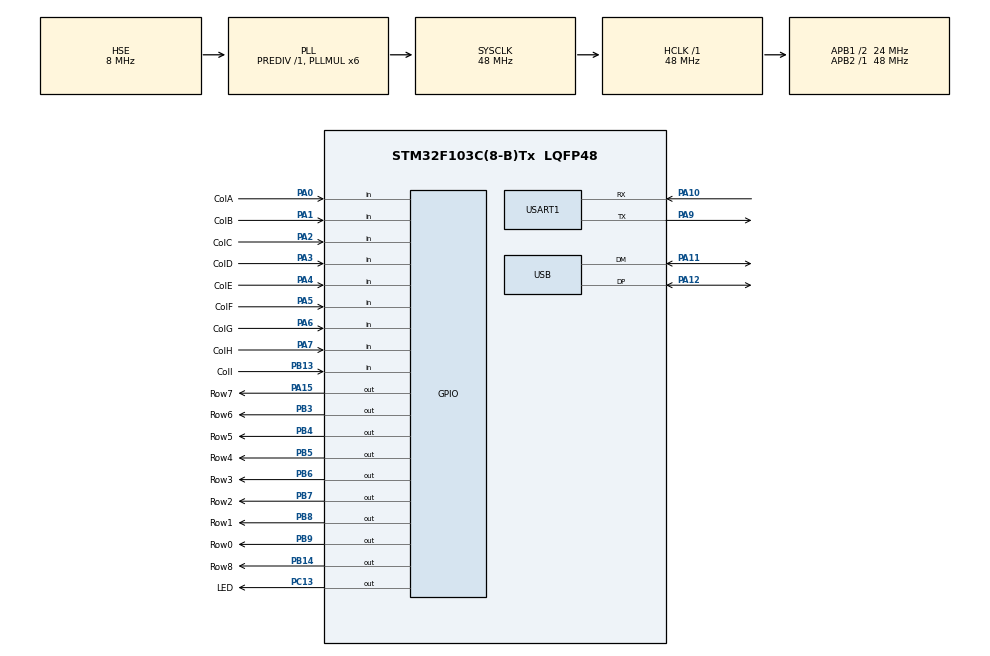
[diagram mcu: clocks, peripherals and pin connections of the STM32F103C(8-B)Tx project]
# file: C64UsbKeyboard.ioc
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FREERTOS.Tasks01=defaultTask,24,128,StartDefaultTask,Default,NULL,Dynamic,NULL,NULL;applicationTask,27,1024,StartApplicationTask,Default,NULL,Static,applicationTaskBuffer,applicationTaskControlBlock
FREERTOS.configUSE_NEWLIB_REENTRANT=1
Mcu.Family=STM32F1
Mcu.Name=STM32F103C(8-B)Tx
Mcu.Package=LQFP48
NVIC.PriorityGroup=NVIC_PRIORITYGROUP_4
NVIC.TIM4_IRQn=true\:15\:0\:false\:false\:true\:false\:false\:true\:true
NVIC.TimeBase=TIM4_IRQn
NVIC.TimeBaseIP=TIM4
NVIC.USART1_IRQn=true\:5\:0\:false\:false\:true\:true\:true\:true\:true
NVIC.USB_LP_CAN1_RX0_IRQn=true\:5\:0\:false\:false\:true\:true\:false\:true\:true
PA0-WKUP.GPIO_Label=ColA
PA0-WKUP.GPIO_PuPd=GPIO_PULLUP
PA0-WKUP.Signal=GPIO_Input
PA1.GPIO_Label=ColB
PA1.GPIO_PuPd=GPIO_PULLUP
PA1.Signal=GPIO_Input
PA10.Mode=Asynchronous
PA10.Signal=USART1_RX
PA11.Mode=Device
PA11.Signal=USB_DM
PA12.Mode=Device
PA12.Signal=USB_DP
PA13.Mode=Serial_Wire
PA13.Signal=SYS_JTMS-SWDIO
PA14.Mode=Serial_Wire
PA14.Signal=SYS_JTCK-SWCLK
PA15.GPIO_Label=Row7
PA15.Signal=GPIO_Output
PA2.GPIO_Label=ColC
PA2.GPIO_PuPd=GPIO_PULLUP
PA2.Signal=GPIO_Input
PA3.GPIO_Label=ColD
PA3.GPIO_PuPd=GPIO_PULLUP
PA3.Signal=GPIO_Input
PA4.GPIO_Label=ColE
PA4.GPIO_PuPd=GPIO_PULLUP
PA4.Signal=GPIO_Input
PA5.GPIO_Label=ColF
PA5.GPIO_PuPd=GPIO_PULLUP
PA5.Signal=GPIO_Input
PA6.GPIO_Label=ColG
PA6.GPIO_PuPd=GPIO_PULLUP
PA6.Signal=GPIO_Input
PA7.GPIO_Label=ColH
PA7.GPIO_PuPd=GPIO_PULLUP
PA7.Signal=GPIO_Input
PA9.Mode=Asynchronous
PA9.Signal=USART1_TX
PB13.GPIO_Label=ColI
PB13.GPIO_PuPd=GPIO_PULLUP
PB13.Signal=GPIO_Input
PB14.GPIO_Label=Row8
PB14.Signal=GPIO_Output
PB3.GPIO_Label=Row6
PB3.Signal=GPIO_Output
PB4.GPIO_Label=Row5
PB4.Signal=GPIO_Output
PB5.GPIO_Label=Row4
PB5.Signal=GPIO_Output
PB6.GPIO_Label=Row3
PB6.Signal=GPIO_Output
PB7.GPIO_Label=Row2
PB7.Signal=GPIO_Output
PB8.GPIO_Label=Row1
PB8.Signal=GPIO_Output
PB9.GPIO_Label=Row0
PB9.Signal=GPIO_Output
PC13-TAMPER-RTC.GPIO_Label=LED
PC13-TAMPER-RTC.Signal=GPIO_Output
PC14-OSC32_IN.Mode=LSE-External-Oscillator
PC14-OSC32_IN.Signal=RCC_OSC32_IN
PC15-OSC32_OUT.Mode=LSE-External-Oscillator
PC15-OSC32_OUT.Signal=RCC_OSC32_OUT
PD0-OSC_IN.Mode=HSE-External-Oscillator
PD0-OSC_IN.Signal=RCC_OSC_IN
PD1-OSC_OUT.Mode=HSE-External-Oscillator
PD1-OSC_OUT.Signal=RCC_OSC_OUT
ProjectManager.HeapSize=0x200
ProjectManager.StackSize=0x400
ProjectManager.TargetToolchain=STM32CubeIDE
RCC.AHBFreq_Value=48000000
RCC.APB1CLKDivider=RCC_HCLK_DIV2
RCC.APB1Freq_Value=24000000
RCC.APB1TimFreq_Value=48000000
RCC.APB2Freq_Value=48000000
RCC.APB2TimFreq_Value=48000000
RCC.HCLKFreq_Value=48000000
RCC.PLLMUL=RCC_PLL_MUL6
RCC.SYSCLKFreq_VALUE=48000000
RCC.SYSCLKSource=RCC_SYSCLKSOURCE_PLLCLK
RCC.USBFreq_Value=48000000
USART1.VirtualMode=VM_ASYNC
USB_DEVICE.CLASS_NAME_FS=HID
USB_DEVICE.PRODUCT_STRING_HID_FS=C64Keyboard
USB_DEVICE.VirtualMode=Hid
USB_DEVICE.VirtualModeFS=Hid_FS
VP_FREERTOS_VS_CMSIS_V2.Mode=CMSIS_V2
VP_SYS_VS_tim4.Mode=TIM4
VP_USB_DEVICE_VS_USB_DEVICE_HID_FS.Mode=HID_FS
board=custom

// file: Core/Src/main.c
/* USER CODE BEGIN Header */
/**
  ******************************************************************************
  * @file           : main.c
  * @brief          : Main program body
  ******************************************************************************
  * @attention
  *
  * Copyright (c) 2026 STMicroelectronics.
  * All rights reserved.
  *
  * This software is licensed under terms that can be found in the LICENSE file
  * in the root directory of this software component.
  * If no LICENSE file comes with this software, it is provided AS-IS.
  *
  ******************************************************************************
  */

// https://www.instructables.com/STM32-As-HID-USB-Keyboard-STM32-Tutorials/

/* USER CODE END Header */
#include "main.h"
#include "cmsis_os.h"
#include "usb_device.h"

/* USER CODE BEGIN Includes */
#include "usbd_hid.h"
#include "Instances/common.h"
#include "Tasks/systemTask.h"
#include "Tasks/applicationTask.h"
/* USER CODE END Includes */

typedef StaticTask_t osStaticThreadDef_t;

UART_HandleTypeDef huart1;

/* Definitions for defaultTask */
osThreadId_t defaultTaskHandle;
const osThreadAttr_t defaultTask_attributes = {
  .name = "defaultTask",
  .stack_size = 128 * 4,
  .priority = (osPriority_t) osPriorityNormal,
};
/* Definitions for applicationTask */
osThreadId_t applicationTaskHandle;
uint32_t applicationTaskBuffer[ 512 ];
osStaticThreadDef_t applicationTaskControlBlock;
const osThreadAttr_t applicationTask_attributes = {
  .name = "applicationTask",
  .cb_mem = &applicationTaskControlBlock,
  .cb_size = sizeof(applicationTaskControlBlock),
  .stack_mem = &applicationTaskBuffer[0],
  .stack_size = sizeof(applicationTaskBuffer),
  .priority = (osPriority_t) osPriorityNormal3,
};

void SystemClock_Config(void);
static void MX_GPIO_Init(void);
static void MX_USART1_UART_Init(void);
void StartDefaultTask(void *argument);
void StartApplicationTask(void *argument);

int main(void)
{

  /* MCU Configuration--------------------------------------------------------*/

  /* Reset of all peripherals, Initializes the Flash interface and the Systick. */
  HAL_Init();

  /* Configure the system clock */
  SystemClock_Config();

  /* Initialize all configured peripherals */
  MX_GPIO_Init();
  MX_USART1_UART_Init();
  /* USER CODE BEGIN 2 */

  common_init();

  /* USER CODE END 2 */

  /* Init scheduler */
  osKernelInitialize();

  /* Create the thread(s) */
  /* creation of defaultTask */
  defaultTaskHandle = osThreadNew(StartDefaultTask, NULL, &defaultTask_attributes);

  /* creation of applicationTask */
  applicationTaskHandle = osThreadNew(StartApplicationTask, NULL, &applicationTask_attributes);

  /* Start scheduler */
  osKernelStart();

  /* We should never get here as control is now taken by the scheduler */

  /* Infinite loop */
  while (1)
  {

  }
}

void SystemClock_Config(void)
{
  RCC_OscInitTypeDef RCC_OscInitStruct = {0};
  RCC_ClkInitTypeDef RCC_ClkInitStruct = {0};
  RCC_PeriphCLKInitTypeDef PeriphClkInit = {0};

  /** Initializes the RCC Oscillators according to the specified parameters
  * in the RCC_OscInitTypeDef structure.
  */
  RCC_OscInitStruct.OscillatorType = RCC_OSCILLATORTYPE_HSE;
  RCC_OscInitStruct.HSEState = RCC_HSE_ON;
  RCC_OscInitStruct.HSEPredivValue = RCC_HSE_PREDIV_DIV1;
  RCC_OscInitStruct.HSIState = RCC_HSI_ON;
  RCC_OscInitStruct.PLL.PLLState = RCC_PLL_ON;
  RCC_OscInitStruct.PLL.PLLSource = RCC_PLLSOURCE_HSE;
  RCC_OscInitStruct.PLL.PLLMUL = RCC_PLL_MUL6;
  if (HAL_RCC_OscConfig(&RCC_OscInitStruct) != HAL_OK)
  {
    Error_Handler();
  }

  /** Initializes the CPU, AHB and APB buses clocks
  */
  RCC_ClkInitStruct.ClockType = RCC_CLOCKTYPE_HCLK|RCC_CLOCKTYPE_SYSCLK
                              |RCC_CLOCKTYPE_PCLK1|RCC_CLOCKTYPE_PCLK2;
  RCC_ClkInitStruct.SYSCLKSource = RCC_SYSCLKSOURCE_PLLCLK;
  RCC_ClkInitStruct.AHBCLKDivider = RCC_SYSCLK_DIV1;
  RCC_ClkInitStruct.APB1CLKDivider = RCC_HCLK_DIV2;
  RCC_ClkInitStruct.APB2CLKDivider = RCC_HCLK_DIV1;

  if (HAL_RCC_ClockConfig(&RCC_ClkInitStruct, FLASH_LATENCY_1) != HAL_OK)
  {
    Error_Handler();
  }
  PeriphClkInit.PeriphClockSelection = RCC_PERIPHCLK_USB;
  PeriphClkInit.UsbClockSelection = RCC_USBCLKSOURCE_PLL;
  if (HAL_RCCEx_PeriphCLKConfig(&PeriphClkInit) != HAL_OK)
  {
    Error_Handler();
  }
}

static void MX_USART1_UART_Init(void)
{

  huart1.Instance = USART1;
  huart1.Init.BaudRate = 115200;
  huart1.Init.WordLength = UART_WORDLENGTH_8B;
  huart1.Init.StopBits = UART_STOPBITS_1;
  huart1.Init.Parity = UART_PARITY_NONE;
  huart1.Init.Mode = UART_MODE_TX_RX;
  huart1.Init.HwFlowCtl = UART_HWCONTROL_NONE;
  huart1.Init.OverSampling = UART_OVERSAMPLING_16;
  if (HAL_UART_Init(&huart1) != HAL_OK)
  {
    Error_Handler();
  }

}

static void MX_GPIO_Init(void)
{
  GPIO_InitTypeDef GPIO_InitStruct = {0};

  /* GPIO Ports Clock Enable */
  __HAL_RCC_GPIOC_CLK_ENABLE();
  __HAL_RCC_GPIOD_CLK_ENABLE();
  __HAL_RCC_GPIOA_CLK_ENABLE();
  __HAL_RCC_GPIOB_CLK_ENABLE();

  /*Configure GPIO pin Output Level */
  HAL_GPIO_WritePin(LED_GPIO_Port, LED_Pin, GPIO_PIN_RESET);

  /*Configure GPIO pin Output Level */
  HAL_GPIO_WritePin(GPIOB, Row8_Pin|Row6_Pin|Row5_Pin|Row4_Pin
                          |Row3_Pin|Row2_Pin|Row1_Pin|Row0_Pin, GPIO_PIN_RESET);

  /*Configure GPIO pin Output Level */
  HAL_GPIO_WritePin(Row7_GPIO_Port, Row7_Pin, GPIO_PIN_RESET);

  /*Configure GPIO pin : LED_Pin */
  GPIO_InitStruct.Pin = LED_Pin;
  GPIO_InitStruct.Mode = GPIO_MODE_OUTPUT_PP;
  GPIO_InitStruct.Pull = GPIO_NOPULL;
  GPIO_InitStruct.Speed = GPIO_SPEED_FREQ_LOW;
  HAL_GPIO_Init(LED_GPIO_Port, &GPIO_InitStruct);

  /*Configure GPIO pins : ColA_Pin ColB_Pin ColC_Pin ColD_Pin
                           ColE_Pin ColF_Pin ColG_Pin ColH_Pin */
  GPIO_InitStruct.Pin = ColA_Pin|ColB_Pin|ColC_Pin|ColD_Pin
                          |ColE_Pin|ColF_Pin|ColG_Pin|ColH_Pin;
  GPIO_InitStruct.Mode = GPIO_MODE_INPUT;
  GPIO_InitStruct.Pull = GPIO_PULLUP;
  HAL_GPIO_Init(GPIOA, &GPIO_InitStruct);

  /*Configure GPIO pin : ColI_Pin */
  GPIO_InitStruct.Pin = ColI_Pin;
  GPIO_InitStruct.Mode = GPIO_MODE_INPUT;
  GPIO_InitStruct.Pull = GPIO_PULLUP;
  HAL_GPIO_Init(ColI_GPIO_Port, &GPIO_InitStruct);

  /*Configure GPIO pins : Row8_Pin Row6_Pin Row5_Pin Row4_Pin
                           Row3_Pin Row2_Pin Row1_Pin Row0_Pin */
  GPIO_InitStruct.Pin = Row8_Pin|Row6_Pin|Row5_Pin|Row4_Pin
                          |Row3_Pin|Row2_Pin|Row1_Pin|Row0_Pin;
  GPIO_InitStruct.Mode = GPIO_MODE_OUTPUT_PP;
  GPIO_InitStruct.Pull = GPIO_NOPULL;
  GPIO_InitStruct.Speed = GPIO_SPEED_FREQ_LOW;
  HAL_GPIO_Init(GPIOB, &GPIO_InitStruct);

  /*Configure GPIO pin : Row7_Pin */
  GPIO_InitStruct.Pin = Row7_Pin;
  GPIO_InitStruct.Mode = GPIO_MODE_OUTPUT_PP;
  GPIO_InitStruct.Pull = GPIO_NOPULL;
  GPIO_InitStruct.Speed = GPIO_SPEED_FREQ_LOW;
  HAL_GPIO_Init(Row7_GPIO_Port, &GPIO_InitStruct);

}

void StartDefaultTask(void *argument)
{
  /* init code for USB_DEVICE */
  MX_USB_DEVICE_Init();
  /* USER CODE BEGIN 5 */

  masterSerialTask(argument);

  /* Infinite loop */
  for(;;)
  {
    osDelay(1);
  }
  /* USER CODE END 5 */
}

void StartApplicationTask(void *argument)
{
  /* USER CODE BEGIN StartApplicationTask */

	applicationTask(argument);

  /* Infinite loop */
  for(;;)
  {
    osDelay(1);
  }
  /* USER CODE END StartApplicationTask */
}

void HAL_TIM_PeriodElapsedCallback(TIM_HandleTypeDef *htim)
{
  if (htim->Instance == TIM4)
  {
    HAL_IncTick();
  }
}

void Error_Handler(void)
{
  __disable_irq();
  while (1)
  {
  }
}
